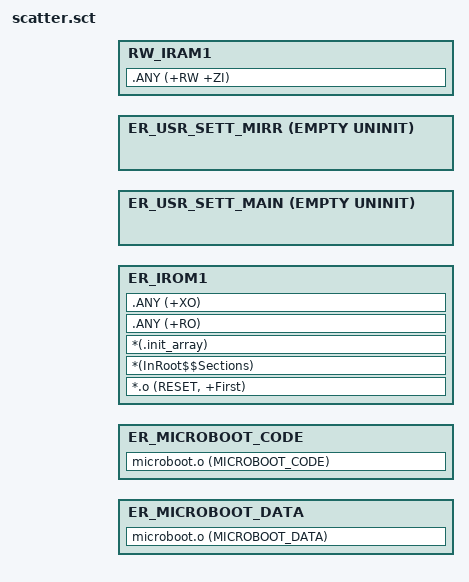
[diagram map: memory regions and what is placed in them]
#! armclang --target=arm-arm-none-eabi -march=armv7-a -E -x c -I ../source/main
; **************************************************************************************************
; ***                    Scatter-Loading Description File generated by uVision                   ***
; **************************************************************************************************

#include "flash_map.h"

LR_MICROBOOT MICROBOOT_START
{
    ER_MICROBOOT_DATA MICROBOOT_START
    {
        microboot.o (MICROBOOT_DATA)
    }
    ER_MICROBOOT_CODE +0
    {
        microboot.o (MICROBOOT_CODE)
    }
}

; Memory map (scatter syntax)
LR_IROM1 APPL_START (FLASH_SIZE - (APPL_START - FLASH_START))
{    
    ER_IROM1 APPL_START
    {
        *.o (RESET, +First)
        *(InRoot$$Sections)
        *(.init_array)
        .ANY (+RO)
        .ANY (+XO)
    }

    ER_USR_SETT_MAIN USR_SETT_MAIN_START EMPTY UNINIT SETT_PAGE_SIZE
    {
    }
    ER_USR_SETT_MIRR USR_SETT_MIRR_START EMPTY UNINIT SETT_PAGE_SIZE
    {
    }
    
    ; RW data
    RW_IRAM1 RAM_START RAM_SIZE
    {  
        .ANY (+RW +ZI)
    }
}
